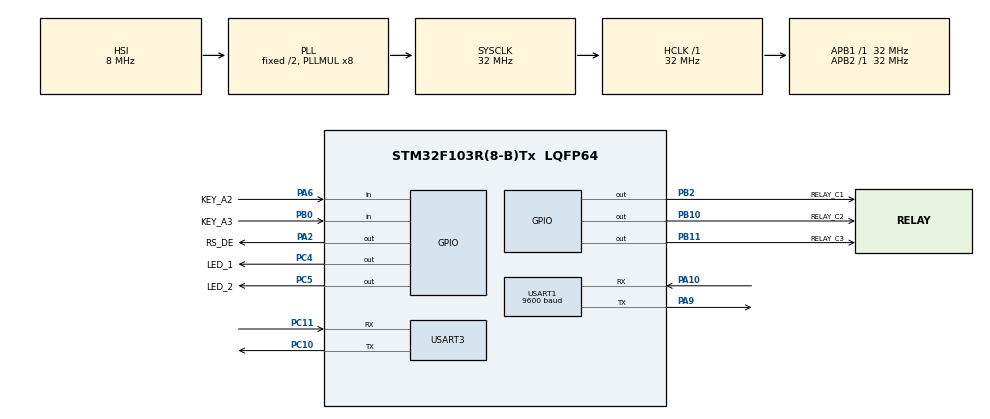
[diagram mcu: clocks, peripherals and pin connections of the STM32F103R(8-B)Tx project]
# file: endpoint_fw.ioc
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FREERTOS.HEAP_NUMBER=1
FREERTOS.Tasks01=defaultTask,0,512,StartDefaultTask,Default,NULL,Dynamic,NULL,NULL
FREERTOS.configTOTAL_HEAP_SIZE=5000
Mcu.Family=STM32F1
Mcu.Name=STM32F103R(8-B)Tx
Mcu.Package=LQFP64
NVIC.PriorityGroup=NVIC_PRIORITYGROUP_4
NVIC.USART1_IRQn=true\:5\:0\:true\:false\:true\:true\:true\:true
PA10.Mode=Asynchronous
PA10.Signal=USART1_RX
PA13.Mode=Serial_Wire
PA13.Signal=SYS_JTMS-SWDIO
PA14.Mode=Serial_Wire
PA14.Signal=SYS_JTCK-SWCLK
PA2.GPIO_Label=RS_DE
PA2.GPIO_Speed=GPIO_SPEED_FREQ_MEDIUM
PA2.Signal=GPIO_Output
PA6.GPIO_Label=KEY_A2
PA6.GPIO_PuPd=GPIO_PULLUP
PA6.Signal=GPIO_Input
PA9.Mode=Asynchronous
PA9.Signal=USART1_TX
PB0.GPIO_Label=KEY_A3
PB0.GPIO_PuPd=GPIO_PULLUP
PB0.Signal=GPIO_Input
PB10.GPIO_Label=RELAY_C2
PB10.GPIO_Speed=GPIO_SPEED_FREQ_MEDIUM
PB10.Signal=GPIO_Output
PB11.GPIO_Label=RELAY_C3
PB11.GPIO_Speed=GPIO_SPEED_FREQ_MEDIUM
PB11.Signal=GPIO_Output
PB2.GPIO_Label=RELAY_C1
PB2.GPIO_Speed=GPIO_SPEED_FREQ_MEDIUM
PB2.Signal=GPIO_Output
PC10.Mode=Asynchronous
PC10.Signal=USART3_TX
PC11.Mode=Asynchronous
PC11.Signal=USART3_RX
PC4.GPIO_Label=LED_1
PC4.GPIO_Speed=GPIO_SPEED_FREQ_MEDIUM
PC4.Signal=GPIO_Output
PC5.GPIO_Label=LED_2
PC5.GPIO_Speed=GPIO_SPEED_FREQ_MEDIUM
PC5.Signal=GPIO_Output
PD0-OSC_IN.Mode=HSE-External-Oscillator
PD0-OSC_IN.Signal=RCC_OSC_IN
PD1-OSC_OUT.Mode=HSE-External-Oscillator
PD1-OSC_OUT.Signal=RCC_OSC_OUT
ProjectManager.HeapSize=0x200
ProjectManager.StackSize=0x400
ProjectManager.TargetToolchain=Makefile
RCC.AHBFreq_Value=32000000
RCC.APB1Freq_Value=32000000
RCC.APB1TimFreq_Value=32000000
RCC.APB2Freq_Value=32000000
RCC.APB2TimFreq_Value=32000000
RCC.HCLKFreq_Value=32000000
RCC.PLLMUL=RCC_PLL_MUL8
RCC.SYSCLKFreq_VALUE=32000000
RCC.SYSCLKSource=RCC_SYSCLKSOURCE_PLLCLK
RCC.USBFreq_Value=32000000
USART1.BaudRate=9600
USART1.VirtualMode=VM_ASYNC
USART3.VirtualMode=VM_ASYNC
VP_FREERTOS_VS_CMSIS_V1.Mode=CMSIS_V1
VP_TIM4_VS_ClockSourceINT.Mode=Internal
board=endpoint_fw

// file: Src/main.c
/* USER CODE BEGIN Header */
/**
  ******************************************************************************
  * @file           : main.c
  * @brief          : Main program body
  ******************************************************************************
  * @attention
  *
  * <h2><center>&copy; Copyright (c) 2019 STMicroelectronics.
  * All rights reserved.</center></h2>
  *
  * This software component is licensed by ST under Ultimate Liberty license
  * SLA0044, the "License"; You may not use this file except in compliance with
  * the License. You may obtain a copy of the License at:
  *                             www.st.com/SLA0044
  *
  ******************************************************************************
  */
/* USER CODE END Header */

#include "main.h"
#include "cmsis_os.h"

TIM_HandleTypeDef htim4;

UART_HandleTypeDef huart1;
UART_HandleTypeDef huart3;

osThreadId defaultTaskHandle;
/* USER CODE BEGIN PV */
/* Private variables ---------------------------------------------------------*/

/* USER CODE END PV */

void SystemClock_Config(void);
static void MX_GPIO_Init(void);
static void MX_USART1_UART_Init(void);
static void MX_USART3_UART_Init(void);
static void MX_TIM4_Init(void);
void StartDefaultTask(void const * argument);

/* USER CODE BEGIN PFP */
/* Private function prototypes -----------------------------------------------*/
void app();
/* USER CODE END PFP */

int main(void)
{

  /* MCU Configuration--------------------------------------------------------*/

  /* Reset of all peripherals, Initializes the Flash interface and the Systick. */
  HAL_Init();

  /* Configure the system clock */
  SystemClock_Config();

  /* Initialize all configured peripherals */
  MX_GPIO_Init();
  MX_USART1_UART_Init();
  MX_USART3_UART_Init();
  MX_TIM4_Init();

  /* Create the thread(s) */
  /* definition and creation of defaultTask */
  osThreadDef(defaultTask, StartDefaultTask, osPriorityNormal, 0, 512);
  defaultTaskHandle = osThreadCreate(osThread(defaultTask), NULL);

  /* Start scheduler */
  osKernelStart();

  /* We should never get here as control is now taken by the scheduler */

  /* Infinite loop */
  while (1)
  {

  }
}

void SystemClock_Config(void)
{
  RCC_OscInitTypeDef RCC_OscInitStruct = {0};
  RCC_ClkInitTypeDef RCC_ClkInitStruct = {0};

  /** Initializes the CPU, AHB and APB busses clocks
  */
  RCC_OscInitStruct.OscillatorType = RCC_OSCILLATORTYPE_HSI;
  RCC_OscInitStruct.HSIState = RCC_HSI_ON;
  RCC_OscInitStruct.HSICalibrationValue = RCC_HSICALIBRATION_DEFAULT;
  RCC_OscInitStruct.PLL.PLLState = RCC_PLL_ON;
  RCC_OscInitStruct.PLL.PLLSource = RCC_PLLSOURCE_HSI_DIV2;
  RCC_OscInitStruct.PLL.PLLMUL = RCC_PLL_MUL8;
  if (HAL_RCC_OscConfig(&RCC_OscInitStruct) != HAL_OK)
  {
    Error_Handler();
  }
  /** Initializes the CPU, AHB and APB busses clocks
  */
  RCC_ClkInitStruct.ClockType = RCC_CLOCKTYPE_HCLK|RCC_CLOCKTYPE_SYSCLK
                              |RCC_CLOCKTYPE_PCLK1|RCC_CLOCKTYPE_PCLK2;
  RCC_ClkInitStruct.SYSCLKSource = RCC_SYSCLKSOURCE_PLLCLK;
  RCC_ClkInitStruct.AHBCLKDivider = RCC_SYSCLK_DIV1;
  RCC_ClkInitStruct.APB1CLKDivider = RCC_HCLK_DIV1;
  RCC_ClkInitStruct.APB2CLKDivider = RCC_HCLK_DIV1;

  if (HAL_RCC_ClockConfig(&RCC_ClkInitStruct, FLASH_LATENCY_1) != HAL_OK)
  {
    Error_Handler();
  }
}

static void MX_TIM4_Init(void)
{

  TIM_ClockConfigTypeDef sClockSourceConfig = {0};
  TIM_MasterConfigTypeDef sMasterConfig = {0};

  htim4.Instance = TIM4;
  htim4.Init.Prescaler = 0;
  htim4.Init.CounterMode = TIM_COUNTERMODE_UP;
  htim4.Init.Period = 0;
  htim4.Init.ClockDivision = TIM_CLOCKDIVISION_DIV1;
  htim4.Init.AutoReloadPreload = TIM_AUTORELOAD_PRELOAD_DISABLE;
  if (HAL_TIM_Base_Init(&htim4) != HAL_OK)
  {
    Error_Handler();
  }
  sClockSourceConfig.ClockSource = TIM_CLOCKSOURCE_INTERNAL;
  if (HAL_TIM_ConfigClockSource(&htim4, &sClockSourceConfig) != HAL_OK)
  {
    Error_Handler();
  }
  sMasterConfig.MasterOutputTrigger = TIM_TRGO_RESET;
  sMasterConfig.MasterSlaveMode = TIM_MASTERSLAVEMODE_DISABLE;
  if (HAL_TIMEx_MasterConfigSynchronization(&htim4, &sMasterConfig) != HAL_OK)
  {
    Error_Handler();
  }

}

static void MX_USART1_UART_Init(void)
{

  huart1.Instance = USART1;
  huart1.Init.BaudRate = 9600;
  huart1.Init.WordLength = UART_WORDLENGTH_8B;
  huart1.Init.StopBits = UART_STOPBITS_1;
  huart1.Init.Parity = UART_PARITY_NONE;
  huart1.Init.Mode = UART_MODE_TX_RX;
  huart1.Init.HwFlowCtl = UART_HWCONTROL_NONE;
  huart1.Init.OverSampling = UART_OVERSAMPLING_16;
  if (HAL_UART_Init(&huart1) != HAL_OK)
  {
    Error_Handler();
  }

}

static void MX_USART3_UART_Init(void)
{

  huart3.Instance = USART3;
  huart3.Init.BaudRate = 115200;
  huart3.Init.WordLength = UART_WORDLENGTH_8B;
  huart3.Init.StopBits = UART_STOPBITS_1;
  huart3.Init.Parity = UART_PARITY_NONE;
  huart3.Init.Mode = UART_MODE_TX_RX;
  huart3.Init.HwFlowCtl = UART_HWCONTROL_NONE;
  huart3.Init.OverSampling = UART_OVERSAMPLING_16;
  if (HAL_UART_Init(&huart3) != HAL_OK)
  {
    Error_Handler();
  }

}

static void MX_GPIO_Init(void)
{
  GPIO_InitTypeDef GPIO_InitStruct = {0};

  /* GPIO Ports Clock Enable */
  __HAL_RCC_GPIOC_CLK_ENABLE();
  __HAL_RCC_GPIOD_CLK_ENABLE();
  __HAL_RCC_GPIOA_CLK_ENABLE();
  __HAL_RCC_GPIOB_CLK_ENABLE();

  /*Configure GPIO pin Output Level */
  HAL_GPIO_WritePin(RS_DE_GPIO_Port, RS_DE_Pin, GPIO_PIN_RESET);

  /*Configure GPIO pin Output Level */
  HAL_GPIO_WritePin(GPIOC, LED_1_Pin|LED_2_Pin, GPIO_PIN_RESET);

  /*Configure GPIO pin Output Level */
  HAL_GPIO_WritePin(GPIOB, RELAY_C1_Pin|RELAY_C2_Pin|RELAY_C3_Pin, GPIO_PIN_RESET);

  /*Configure GPIO pins : PC13 PC14 PC15 PC0
                           PC1 PC2 PC3 PC6
                           PC7 PC8 PC9 PC12 */
  GPIO_InitStruct.Pin = GPIO_PIN_13|GPIO_PIN_14|GPIO_PIN_15|GPIO_PIN_0
                          |GPIO_PIN_1|GPIO_PIN_2|GPIO_PIN_3|GPIO_PIN_6
                          |GPIO_PIN_7|GPIO_PIN_8|GPIO_PIN_9|GPIO_PIN_12;
  GPIO_InitStruct.Mode = GPIO_MODE_ANALOG;
  HAL_GPIO_Init(GPIOC, &GPIO_InitStruct);

  /*Configure GPIO pins : PA0 PA1 PA3 PA4
                           PA5 PA7 PA8 PA11
                           PA12 PA15 */
  GPIO_InitStruct.Pin = GPIO_PIN_0|GPIO_PIN_1|GPIO_PIN_3|GPIO_PIN_4
                          |GPIO_PIN_5|GPIO_PIN_7|GPIO_PIN_8|GPIO_PIN_11
                          |GPIO_PIN_12|GPIO_PIN_15;
  GPIO_InitStruct.Mode = GPIO_MODE_ANALOG;
  HAL_GPIO_Init(GPIOA, &GPIO_InitStruct);

  /*Configure GPIO pin : RS_DE_Pin */
  GPIO_InitStruct.Pin = RS_DE_Pin;
  GPIO_InitStruct.Mode = GPIO_MODE_OUTPUT_PP;
  GPIO_InitStruct.Pull = GPIO_NOPULL;
  GPIO_InitStruct.Speed = GPIO_SPEED_FREQ_MEDIUM;
  HAL_GPIO_Init(RS_DE_GPIO_Port, &GPIO_InitStruct);

  /*Configure GPIO pin : KEY_A2_Pin */
  GPIO_InitStruct.Pin = KEY_A2_Pin;
  GPIO_InitStruct.Mode = GPIO_MODE_INPUT;
  GPIO_InitStruct.Pull = GPIO_PULLUP;
  HAL_GPIO_Init(KEY_A2_GPIO_Port, &GPIO_InitStruct);

  /*Configure GPIO pins : LED_1_Pin LED_2_Pin */
  GPIO_InitStruct.Pin = LED_1_Pin|LED_2_Pin;
  GPIO_InitStruct.Mode = GPIO_MODE_OUTPUT_PP;
  GPIO_InitStruct.Pull = GPIO_NOPULL;
  GPIO_InitStruct.Speed = GPIO_SPEED_FREQ_MEDIUM;
  HAL_GPIO_Init(GPIOC, &GPIO_InitStruct);

  /*Configure GPIO pin : KEY_A3_Pin */
  GPIO_InitStruct.Pin = KEY_A3_Pin;
  GPIO_InitStruct.Mode = GPIO_MODE_INPUT;
  GPIO_InitStruct.Pull = GPIO_PULLUP;
  HAL_GPIO_Init(KEY_A3_GPIO_Port, &GPIO_InitStruct);

  /*Configure GPIO pins : PB1 PB12 PB13 PB14
                           PB15 PB3 PB4 PB5
                           PB6 PB7 PB8 PB9 */
  GPIO_InitStruct.Pin = GPIO_PIN_1|GPIO_PIN_12|GPIO_PIN_13|GPIO_PIN_14
                          |GPIO_PIN_15|GPIO_PIN_3|GPIO_PIN_4|GPIO_PIN_5
                          |GPIO_PIN_6|GPIO_PIN_7|GPIO_PIN_8|GPIO_PIN_9;
  GPIO_InitStruct.Mode = GPIO_MODE_ANALOG;
  HAL_GPIO_Init(GPIOB, &GPIO_InitStruct);

  /*Configure GPIO pins : RELAY_C1_Pin RELAY_C2_Pin RELAY_C3_Pin */
  GPIO_InitStruct.Pin = RELAY_C1_Pin|RELAY_C2_Pin|RELAY_C3_Pin;
  GPIO_InitStruct.Mode = GPIO_MODE_OUTPUT_PP;
  GPIO_InitStruct.Pull = GPIO_NOPULL;
  GPIO_InitStruct.Speed = GPIO_SPEED_FREQ_MEDIUM;
  HAL_GPIO_Init(GPIOB, &GPIO_InitStruct);

  /*Configure GPIO pin : PD2 */
  GPIO_InitStruct.Pin = GPIO_PIN_2;
  GPIO_InitStruct.Mode = GPIO_MODE_ANALOG;
  HAL_GPIO_Init(GPIOD, &GPIO_InitStruct);

}

void StartDefaultTask(void const * argument)
{
  /* USER CODE BEGIN 5 */
  app();
  /* Infinite loop */
  for(;;)
  {
    osDelay(1);
  }
  /* USER CODE END 5 */
}

void Error_Handler(void)
{
  while(1)
  {
  }
}

/************************ (C) COPYRIGHT STMicroelectronics *****END OF FILE****/

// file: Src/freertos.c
/* USER CODE BEGIN Header */
/**
  ******************************************************************************
  * File Name          : freertos.c
  * Description        : Code for freertos applications
  ******************************************************************************
  * @attention
  *
  * <h2><center>&copy; Copyright (c) 2019 STMicroelectronics.
  * All rights reserved.</center></h2>
  *
  * This software component is licensed by ST under Ultimate Liberty license
  * SLA0044, the "License"; You may not use this file except in compliance with
  * the License. You may obtain a copy of the License at:
  *                             www.st.com/SLA0044
  *
  ******************************************************************************
  */
/* USER CODE END Header */

#include "FreeRTOS.h"
#include "task.h"
#include "main.h"

/* GetIdleTaskMemory prototype (linked to static allocation support) */
void vApplicationGetIdleTaskMemory( StaticTask_t **ppxIdleTaskTCBBuffer, StackType_t **ppxIdleTaskStackBuffer, uint32_t *pulIdleTaskStackSize );

/* USER CODE BEGIN GET_IDLE_TASK_MEMORY */
static StaticTask_t xIdleTaskTCBBuffer;
static StackType_t xIdleStack[configMINIMAL_STACK_SIZE];

void vApplicationGetIdleTaskMemory( StaticTask_t **ppxIdleTaskTCBBuffer, StackType_t **ppxIdleTaskStackBuffer, uint32_t *pulIdleTaskStackSize )
{
  *ppxIdleTaskTCBBuffer = &xIdleTaskTCBBuffer;
  *ppxIdleTaskStackBuffer = &xIdleStack[0];
  *pulIdleTaskStackSize = configMINIMAL_STACK_SIZE;
  /* place for user code */
}
/* USER CODE END GET_IDLE_TASK_MEMORY */

/************************ (C) COPYRIGHT STMicroelectronics *****END OF FILE****/
